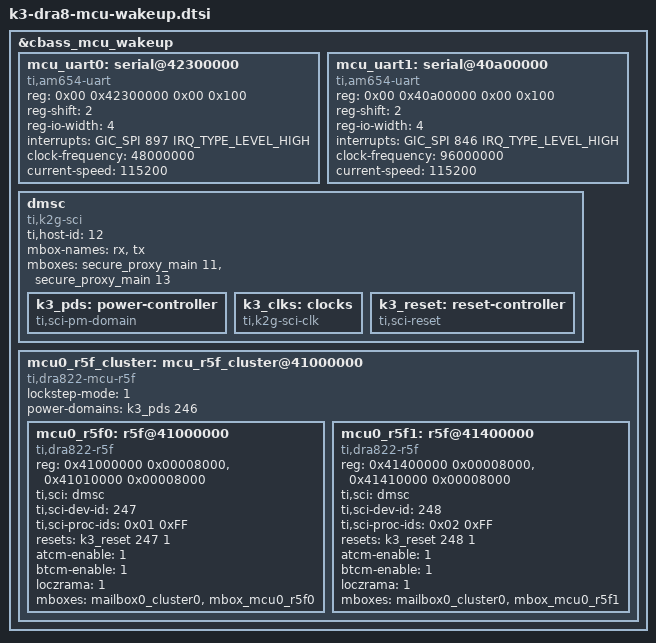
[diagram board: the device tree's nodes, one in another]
// SPDX-License-Identifier: GPL-2.0
/*
 * Device Tree Source for DRA8 SoC Family MCU/WAKEUP Domain peripherals
 *
 * Copyright (C) 2016-2018 Texas Instruments Incorporated - http://www.ti.com/
 */

&cbass_mcu_wakeup {
	mcu_uart0: serial@42300000 {
		compatible = "ti,am654-uart";
		reg = <0x00 0x42300000 0x00 0x100>;
		reg-shift = <2>;
		reg-io-width = <4>;
		interrupts = <GIC_SPI 897 IRQ_TYPE_LEVEL_HIGH>;
		clock-frequency = <48000000>;
		current-speed = <115200>;
	};

	mcu_uart1: serial@40a00000 {
		compatible = "ti,am654-uart";
			reg = <0x00 0x40a00000 0x00 0x100>;
			reg-shift = <2>;
			reg-io-width = <4>;
			interrupts = <GIC_SPI 846 IRQ_TYPE_LEVEL_HIGH>;
			clock-frequency = <96000000>;
			current-speed = <115200>;
	};

	dmsc: dmsc {
		compatible = "ti,k2g-sci";
		ti,host-id = <12>;

		mbox-names = "rx", "tx";

		mboxes= <&secure_proxy_main 11>,
			<&secure_proxy_main 13>;

		k3_pds: power-controller {
			compatible = "ti,sci-pm-domain";
			#power-domain-cells = <1>;
		};

		k3_clks: clocks {
			compatible = "ti,k2g-sci-clk";
			#clock-cells = <2>;
		};

		k3_reset: reset-controller {
			compatible = "ti,sci-reset";
			#reset-cells = <2>;
		};
	};

	mcu0_r5f_cluster: mcu_r5f_cluster@41000000 {
		compatible = "ti,dra822-mcu-r5f";
		lockstep-mode = <1>;
		#address-cells = <1>;
		#size-cells = <1>;
		ranges = <0x41000000 0x00 0x41000000 0x20000>,
			 <0x41400000 0x00 0x41400000 0x20000>;
		power-domains = <&k3_pds 246>;

		mcu0_r5f0: r5f@41000000 {
			compatible = "ti,dra822-r5f";
			reg = <0x41000000 0x00008000>,
			      <0x41010000 0x00008000>;
			reg-names = "atcm", "btcm";
			ti,sci = <&dmsc>;
			ti,sci-dev-id = <247>;
			ti,sci-proc-ids = <0x01 0xFF>;
			resets = <&k3_reset 247 1>;
			atcm-enable = <1>;
			btcm-enable = <1>;
			loczrama = <1>;
			mboxes = <&mailbox0_cluster0 &mbox_mcu0_r5f0>;
		};

		mcu0_r5f1: r5f@41400000 {
			compatible = "ti,dra822-r5f";
			reg = <0x41400000 0x00008000>,
			      <0x41410000 0x00008000>;
			reg-names = "atcm", "btcm";
			ti,sci = <&dmsc>;
			ti,sci-dev-id = <248>;
			ti,sci-proc-ids = <0x02 0xFF>;
			resets = <&k3_reset 248 1>;
			atcm-enable = <1>;
			btcm-enable = <1>;
			loczrama = <1>;
			mboxes = <&mailbox0_cluster0 &mbox_mcu0_r5f1>;
		};
	};
};
